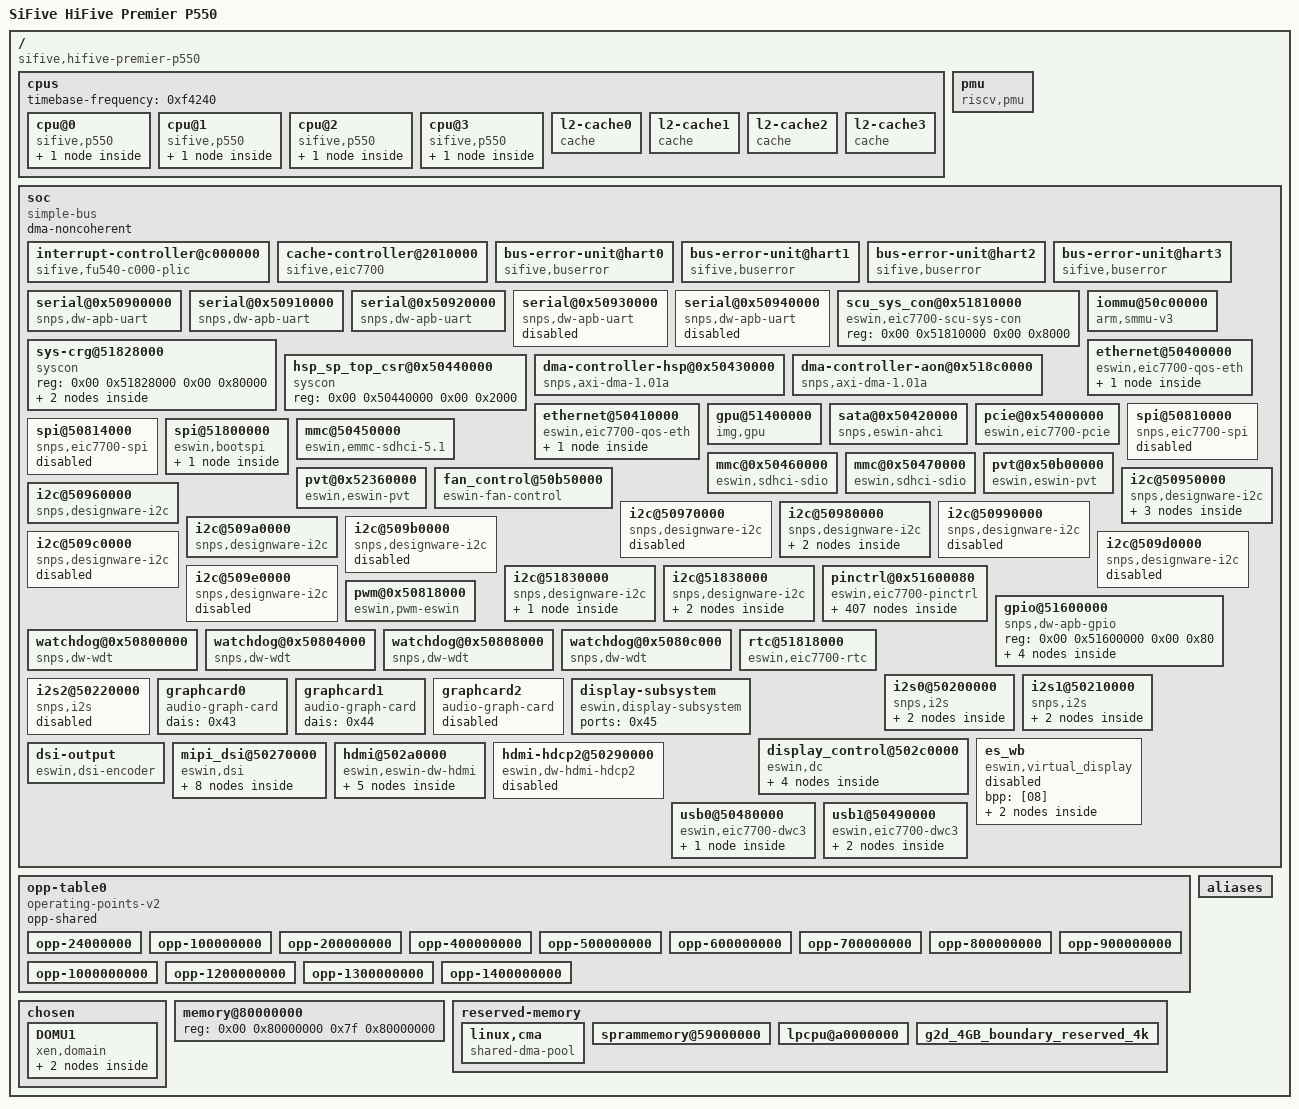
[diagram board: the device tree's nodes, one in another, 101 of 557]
/dts-v1/;

/ {
	#address-cells = <0x02>;
	#size-cells = <0x02>;
	compatible = "sifive,hifive-premier-p550", "eswin,eic7700";
	riscv,physical-memory-regions = <0x00 0x00 0x200 0x00 0x03 0x00 0x00 0x80000000 0x0f 0x80000000 0x1eb7 0x00 0xc0 0x00 0x10 0x00 0x1000e07 0x00>;
	model = "SiFive HiFive Premier P550";

	cpus {
		#address-cells = <0x01>;
		#size-cells = <0x00>;
		timebase-frequency = <0xf4240>;

		cpu@0 {
			compatible = "sifive,p550", "riscv";
			clocks = <0x01 0x1f4>;
			clock-frequency = <0x00>;
			device_type = "cpu";
			d-cache-block-size = <0x40>;
			d-cache-sets = <0x80>;
			d-cache-size = <0x8000>;
			d-tlb-sets = <0x01>;
			d-tlb-size = <0x20>;
			i-cache-block-size = <0x40>;
			i-cache-sets = <0x80>;
			i-cache-size = <0x8000>;
			i-tlb-sets = <0x01>;
			i-tlb-size = <0x20>;
			mmu-type = "riscv,sv48";
			next-level-cache = <0x02>;
			operating-points-v2 = <0x03>;
			reg = <0x00>;
			riscv,isa-base = "rv64i";
			riscv,isa-extensions = "i", "m", "a", "f", "d", "c", "h", "zicsr", "zifencei", "zba", "zbb", "sscofpmf";
			sifive,buserror = <0x04>;
			tlb-split;

			interrupt-controller {
				#interrupt-cells = <0x01>;
				compatible = "riscv,cpu-intc";
				interrupt-controller;
				phandle = <0x0c>;
			};
		};

		cpu@1 {
			compatible = "sifive,p550", "riscv";
			clocks = <0x01 0x1f5>;
			clock-frequency = <0x00>;
			device_type = "cpu";
			d-cache-block-size = <0x40>;
			d-cache-sets = <0x80>;
			d-cache-size = <0x8000>;
			d-tlb-sets = <0x01>;
			d-tlb-size = <0x20>;
			i-cache-block-size = <0x40>;
			i-cache-sets = <0x80>;
			i-cache-size = <0x8000>;
			i-tlb-sets = <0x01>;
			i-tlb-size = <0x20>;
			mmu-type = "riscv,sv48";
			next-level-cache = <0x05>;
			operating-points-v2 = <0x03>;
			reg = <0x01>;
			riscv,isa-base = "rv64i";
			riscv,isa-extensions = "i", "m", "a", "f", "d", "c", "h", "zicsr", "zifencei", "zba", "zbb", "sscofpmf";
			sifive,buserror = <0x06>;
			tlb-split;

			interrupt-controller {
				#interrupt-cells = <0x01>;
				compatible = "riscv,cpu-intc";
				interrupt-controller;
				phandle = <0x0d>;
			};
		};

		cpu@2 {
			compatible = "sifive,p550", "riscv";
			clocks = <0x01 0x1f6>;
			clock-frequency = <0x00>;
			device_type = "cpu";
			d-cache-block-size = <0x40>;
			d-cache-sets = <0x80>;
			d-cache-size = <0x8000>;
			d-tlb-sets = <0x01>;
			d-tlb-size = <0x20>;
			i-cache-block-size = <0x40>;
			i-cache-sets = <0x80>;
			i-cache-size = <0x8000>;
			i-tlb-sets = <0x01>;
			i-tlb-size = <0x20>;
			mmu-type = "riscv,sv48";
			next-level-cache = <0x07>;
			operating-points-v2 = <0x03>;
			reg = <0x02>;
			riscv,isa-base = "rv64i";
			riscv,isa-extensions = "i", "m", "a", "f", "d", "c", "h", "zicsr", "zifencei", "zba", "zbb", "sscofpmf";
			sifive,buserror = <0x08>;
			tlb-split;

			interrupt-controller {
				#interrupt-cells = <0x01>;
				compatible = "riscv,cpu-intc";
				interrupt-controller;
				phandle = <0x0e>;
			};
		};

		cpu@3 {
			compatible = "sifive,p550", "riscv";
			clocks = <0x01 0x1f7>;
			clock-frequency = <0x00>;
			device_type = "cpu";
			d-cache-block-size = <0x40>;
			d-cache-sets = <0x80>;
			d-cache-size = <0x8000>;
			d-tlb-sets = <0x01>;
			d-tlb-size = <0x20>;
			i-cache-block-size = <0x40>;
			i-cache-sets = <0x80>;
			i-cache-size = <0x8000>;
			i-tlb-sets = <0x01>;
			i-tlb-size = <0x20>;
			mmu-type = "riscv,sv48";
			next-level-cache = <0x09>;
			operating-points-v2 = <0x03>;
			reg = <0x03>;
			riscv,isa-base = "rv64i";
			riscv,isa-extensions = "i", "m", "a", "f", "d", "c", "h", "zicsr", "zifencei", "zba", "zbb", "sscofpmf";
			sifive,buserror = <0x0a>;
			tlb-split;

			interrupt-controller {
				#interrupt-cells = <0x01>;
				compatible = "riscv,cpu-intc";
				interrupt-controller;
				phandle = <0x0f>;
			};
		};

		l2-cache0 {
			compatible = "cache";
			cache-block-size = <0x40>;
			cache-level = <0x02>;
			cache-sets = <0x200>;
			cache-size = <0x40000>;
			cache-unified;
			next-level-cache = <0x0b>;
			phandle = <0x02>;
		};

		l2-cache1 {
			compatible = "cache";
			cache-block-size = <0x40>;
			cache-level = <0x02>;
			cache-sets = <0x200>;
			cache-size = <0x40000>;
			cache-unified;
			next-level-cache = <0x0b>;
			phandle = <0x05>;
		};

		l2-cache2 {
			compatible = "cache";
			cache-block-size = <0x40>;
			cache-level = <0x02>;
			cache-sets = <0x200>;
			cache-size = <0x40000>;
			cache-unified;
			next-level-cache = <0x0b>;
			phandle = <0x07>;
		};

		l2-cache3 {
			compatible = "cache";
			cache-block-size = <0x40>;
			cache-level = <0x02>;
			cache-sets = <0x200>;
			cache-size = <0x40000>;
			cache-unified;
			next-level-cache = <0x0b>;
			phandle = <0x09>;
		};
	};

	pmu {
		compatible = "riscv,pmu";
		riscv,event-to-mhpmcounters = <0x01 0x01 0x01 0x02 0x02 0x02 0x04 0x06 0x78 0x10009 0x10009 0x78 0x10019 0x10019 0x78 0x10021 0x10021 0x78>;
		riscv,event-to-mhpmevent = <0x04 0x00 0x202 0x05 0x00 0x4000 0x06 0x00 0x2001 0x10009 0x00 0x102 0x10019 0x00 0x1002 0x10021 0x00 0x802>;
		riscv,raw-event-to-mhpmcounters = <0x00 0x00 0xffffffff 0xff 0x78 0x00 0x01 0xffffffff 0xfffe07ff 0x78 0x00 0x02 0xffffffff 0xfffe00ff 0x78 0x00 0x03 0xfffffffc 0xff 0x78 0x00 0x04 0xffffffc0 0xff 0x78 0x00 0x05 0xffffffff 0xfffffdff 0x78 0x00 0x06 0xfffffe00 0x110204ff 0x78 0x00 0x07 0xffffffff 0xf00000ff 0x78 0x00 0x08 0xfffffe04 0xff 0x78 0x00 0x09 0xffffffff 0xffffc0ff 0x78 0x00 0x0a 0xffffffff 0xf00000ff 0x78 0x00 0x0b 0xffffffff 0xfffffcff 0x78 0x00 0x0c 0xfffffff0 0xff 0x78 0x00 0x0d 0xffffffff 0x800000ff 0x78 0x00 0x0e 0xffffffff 0xf80000ff 0x78 0x00 0x0f 0xfffffffc 0xff 0x78>;
	};

	soc {
		#address-cells = <0x02>;
		#size-cells = <0x02>;
		compatible = "simple-bus";
		ranges;
		dma-noncoherent;

		interrupt-controller@c000000 {
			compatible = "sifive,fu540-c000-plic", "sifive,plic-1.0.0";
			reg = <0x00 0xc000000 0x00 0x4000000>;
			#address-cells = <0x00>;
			#interrupt-cells = <0x01>;
			interrupt-controller;
			interrupts-extended = <0x0c 0xffffffff 0x0c 0x09 0x0d 0xffffffff 0x0d 0x09 0x0e 0xffffffff 0x0e 0x09 0x0f 0xffffffff 0x0f 0x09>;
			riscv,ndev = <0x208>;
			phandle = <0x10>;
		};

		cache-controller@2010000 {
			compatible = "sifive,eic7700";
			cache-block-size = <0x40>;
			cache-level = <0x03>;
			cache-sets = <0x1000>;
			cache-size = <0x400000>;
			cache-unified;
			interrupt-parent = <0x10>;
			interrupts = <0x01 0x03 0x04 0x02>;
			reg = <0x00 0x2010000 0x00 0x4000>;
			phandle = <0x0b>;
		};

		bus-error-unit@hart0 {
			compatible = "sifive,buserror";
			interrupt-parent = <0x10>;
			interrupts = <0x205>;
			reg = <0x00 0x1700000 0x00 0x1000>;
			phandle = <0x04>;
		};

		bus-error-unit@hart1 {
			compatible = "sifive,buserror";
			interrupt-parent = <0x10>;
			interrupts = <0x206>;
			reg = <0x00 0x1701000 0x00 0x1000>;
			phandle = <0x06>;
		};

		bus-error-unit@hart2 {
			compatible = "sifive,buserror";
			interrupt-parent = <0x10>;
			interrupts = <0x207>;
			reg = <0x00 0x1702000 0x00 0x1000>;
			phandle = <0x08>;
		};

		bus-error-unit@hart3 {
			compatible = "sifive,buserror";
			interrupt-parent = <0x10>;
			interrupts = <0x208>;
			reg = <0x00 0x1703000 0x00 0x1000>;
			phandle = <0x0a>;
		};

		serial@0x50900000 {
			compatible = "snps,dw-apb-uart";
			clock-frequency = <0xbebc200>;
			interrupt-parent = <0x10>;
			interrupts = <0x64>;
			reg = <0x00 0x50900000 0x00 0x10000>;
			reg-shift = <0x02>;
			reg-io-width = <0x04>;
			status = "okay";
		};

		serial@0x50910000 {
			compatible = "snps,dw-apb-uart";
			clock-frequency = <0xbebc200>;
			interrupt-parent = <0x10>;
			interrupts = <0x65>;
			reg = <0x00 0x50910000 0x00 0x10000>;
			reg-shift = <0x02>;
			reg-io-width = <0x04>;
			status = "okay";
		};

		serial@0x50920000 {
			compatible = "snps,dw-apb-uart";
			clock-frequency = <0xbebc200>;
			interrupt-parent = <0x10>;
			interrupts = <0x66>;
			reg = <0x00 0x50920000 0x00 0x10000>;
			reg-shift = <0x02>;
			reg-io-width = <0x04>;
			status = "okay";
		};

		serial@0x50930000 {
			compatible = "snps,dw-apb-uart";
			clock-frequency = <0xbebc200>;
			interrupt-parent = <0x10>;
			interrupts = <0x67>;
			reg = <0x00 0x50930000 0x00 0x10000>;
			reg-shift = <0x02>;
			reg-io-width = <0x04>;
			status = "disabled";
		};

		serial@0x50940000 {
			compatible = "snps,dw-apb-uart";
			clock-frequency = <0xbebc200>;
			interrupt-parent = <0x10>;
			interrupts = <0x68>;
			reg = <0x00 0x50940000 0x00 0x10000>;
			reg-shift = <0x02>;
			reg-io-width = <0x04>;
			status = "disabled";
		};

		scu_sys_con@0x51810000 {
			compatible = "eswin,eic7700-scu-sys-con", "syscon", "simple-mfd";
			#syscon-cells = <0x02>;
			#size-cells = <0x02>;
			reg = <0x00 0x51810000 0x00 0x8000>;
			phandle = <0x11>;
		};

		sys-crg@51828000 {
			compatible = "syscon", "simple-mfd";
			reg = <0x00 0x51828000 0x00 0x80000>;
			phandle = <0x15>;

			reset-controller {
				compatible = "eswin,eic7700-reset";
				#reset-cells = <0x02>;
				status = "okay";
				phandle = <0x12>;
			};

			clock-controller {
				compatible = "eswin,eic7700-clock";
				#clock-cells = <0x01>;
				status = "okay";
				phandle = <0x01>;
			};
		};

		hsp_sp_top_csr@0x50440000 {
			compatible = "syscon";
			#size-cells = <0x02>;
			reg = <0x00 0x50440000 0x00 0x2000>;
			phandle = <0x14>;
		};

		iommu@50c00000 {
			compatible = "arm,smmu-v3";
			eswin,syscfg = <0x11 0x3fc>;
			interrupt-parent = <0x10>;
			interrupts = <0x164 0x168 0x165 0x166>;
			interrupt-names = "eventq", "gerror", "priq", "cmdq-sync";
			#iommu-cells = <0x01>;
			reg = <0x00 0x50c00000 0x00 0x100000>;
			resets = <0x12 0x05 0x01 0x12 0x05 0x02 0x12 0x05 0x10 0x12 0x05 0x20 0x12 0x05 0x40 0x12 0x05 0x80 0x12 0x05 0x100 0x12 0x05 0x200 0x12 0x05 0x400 0x12 0x05 0x800>;
			reset-names = "axi_rst", "cfg_rst", "tbu0_rst", "tbu1_rst", "tbu2_rst", "tbu3_rst", "tbu4_rst", "tbu5_rst", "tbu6_rst", "tbu7_rst";
			status = "okay";
			phandle = <0x13>;
		};

		dma-controller-hsp@0x50430000 {
			compatible = "snps,axi-dma-1.01a";
			reg = <0x00 0x50430000 0x00 0x10000>;
			interrupt-parent = <0x10>;
			interrupts = <0x39>;
			clocks = <0x01 0x2b2>;
			clock-names = "core-clk";
			#dma-cells = <0x02>;
			dma-channels = <0x0c>;
			snps,dma-masters = <0x01>;
			snps,priority = <0x00 0x01 0x02 0x03 0x04 0x05 0x06 0x07 0x08 0x09 0x0a 0x0b>;
			snps,data-width = <0x02>;
			snps,block-size = <0x80000 0x80000 0x80000 0x80000 0x80000 0x80000 0x80000 0x80000 0x80000 0x80000 0x80000 0x80000>;
			snps,axi-max-burst-len = <0x10>;
			snps,max-msize = <0x40>;
			resets = <0x12 0x07 0x4000 0x12 0x07 0x100000>;
			reset-names = "arst", "prst";
			iommus = <0x13 0x01>;
			tbus = <0x02>;
			eswin,hsp_sp_csr = <0x14 0x104c>;
			eswin,syscfg = <0x11 0x3004 0x370>;
			status = "okay";
		};

		dma-controller-aon@0x518c0000 {
			compatible = "snps,axi-dma-1.01a";
			#size-cells = <0x02>;
			#address-cells = <0x02>;
			reg = <0x00 0x518c0000 0x00 0x10000>;
			interrupt-parent = <0x10>;
			interrupts = <0x121>;
			clocks = <0x01 0x266>;
			clock-names = "core-clk";
			#dma-cells = <0x02>;
			dma-channels = <0x10>;
			dma-ranges = <0x00 0x80000000 0x00 0x80000000 0x100 0x00>;
			snps,dma-masters = <0x02>;
			snps,priority = <0x00 0x01 0x02 0x03 0x04 0x05 0x06 0x07 0x08 0x09 0x0a 0x0b 0x0c 0x0d 0x0e 0x0f>;
			snps,data-width = <0x03>;
			snps,block-size = <0x80000 0x80000 0x80000 0x80000 0x80000 0x80000 0x80000 0x80000 0x80000 0x80000 0x80000 0x80000 0x80000 0x80000 0x80000 0x80000>;
			snps,axi-max-burst-len = <0x20>;
			snps,max-msize = <0x40>;
			resets = <0x12 0x27 0x01 0x12 0x27 0x02>;
			reset-names = "arst", "prst";
			iommus = <0x13 0x1a>;
			tbus = <0x04>;
			eswin,syscfg = <0x11 0x3004 0x370>;
			status = "okay";
			phandle = <0x1d>;
		};

		ethernet@50400000 {
			compatible = "eswin,eic7700-qos-eth";
			clocks = <0x01 0x226 0x01 0x227 0x01 0x228>;
			clock-names = "app", "stmmaceth", "tx";
			eswin,hsp_sp_csr = <0x14 0x1030 0x100 0x108>;
			eswin,syscrg_csr = <0x15 0x148 0x14c>;
			id = <0x00>;
			interrupts = <0x3d>;
			interrupt-names = "macirq";
			interrupt-parent = <0x10>;
			phy-mode = "rgmii";
			reg = <0x00 0x50400000 0x00 0x10000>;
			resets = <0x12 0x07 0x4000000>;
			reset-names = "ethrst";
			snps,axi-config = <0x16>;
			tbus = <0x02>;
			status = "okay";
			pinctrl-names = "default";
			pinctrl-0 = <0x17>;
			rst-gpios = <0x18 0x0a 0x01>;
			eswin,rgmiisel = <0x19 0x290 0x03>;
			eswin,led-cfgs = <0x6100 0xa40 0x420>;

			stmmac-axi-config {
				snps,blen = <0x00 0x00 0x00 0x00 0x10 0x08 0x04>;
				snps,rd_osr_lmt = <0x02>;
				snps,wr_osr_lmt = <0x02>;
				snps,lpi_en = <0x00>;
				phandle = <0x16>;
			};
		};

		ethernet@50410000 {
			compatible = "eswin,eic7700-qos-eth";
			clocks = <0x01 0x226 0x01 0x227 0x01 0x229>;
			clock-names = "app", "stmmaceth", "tx";
			eswin,hsp_sp_csr = <0x14 0x1034 0x200 0x208>;
			eswin,syscrg_csr = <0x15 0x148 0x14c>;
			id = <0x01>;
			interrupts = <0x46>;
			interrupt-names = "macirq";
			interrupt-parent = <0x10>;
			phy-mode = "rgmii";
			reg = <0x00 0x50410000 0x00 0x10000>;
			resets = <0x12 0x07 0x2000000>;
			reset-names = "ethrst";
			tbus = <0x02>;
			snps,axi-config = <0x1a>;
			status = "okay";
			pinctrl-names = "default";
			pinctrl-0 = <0x1b>;
			rst-gpios = <0x18 0x0f 0x01>;
			eswin,rgmiisel = <0x19 0x294 0x03>;
			eswin,led-cfgs = <0x6100 0xa40 0x420>;

			stmmac-axi-config {
				snps,blen = <0x00 0x00 0x00 0x00 0x10 0x08 0x04>;
				snps,rd_osr_lmt = <0x02>;
				snps,wr_osr_lmt = <0x02>;
				snps,lpi_en = <0x00>;
				phandle = <0x1a>;
			};
		};

		gpu@51400000 {
			compatible = "img,gpu";
			#address-cells = <0x02>;
			#size-cells = <0x02>;
			reg = <0x00 0x51400000 0x00 0xfffff>;
			clocks = <0x01 0x20b 0x01 0x20c 0x01 0x20d>;
			clock-names = "aclk", "gray_clk", "cfg_clk";
			resets = <0x12 0x01 0x01 0x12 0x01 0x02 0x12 0x01 0x04 0x12 0x01 0x08 0x12 0x01 0x10>;
			reset-names = "axi", "cfg", "gray", "jones", "spu";
			interrupt-parent = <0x10>;
			interrupts = <0x0f>;
			status = "okay";
		};

		sata@0x50420000 {
			compatible = "snps,eswin-ahci";
			eswin,hsp_sp_csr = <0x14 0x1050>;
			interrupt-parent = <0x10>;
			interrupt-names = "intrq", "msi", "pme";
			interrupts = <0x3a 0x3b 0x3c>;
			iommus = <0x13 0x0e>;
			ports-implemented = <0x01>;
			reg = <0x00 0x50420000 0x00 0x10000>;
			resets = <0x12 0x07 0x200 0x12 0x07 0x400 0x12 0x07 0x800 0x12 0x07 0x1000 0x12 0x07 0x8000000>;
			reset-names = "asic0", "oob", "pmalive", "rbc", "apb";
			#size-cells = <0x02>;
			tbus = <0x02>;
			dma-ranges = <0x00 0x00 0x00 0xc0000000 0x200 0x00>;
			status = "okay";
			pinctrl-names = "default";
			pinctrl-0 = <0x1c>;
		};

		pcie@0x54000000 {
			compatible = "eswin,eic7700-pcie";
			#address-cells = <0x03>;
			#size-cells = <0x02>;
			clocks = <0x01 0x232 0x01 0x233 0x01 0x234 0x01 0x235>;
			clock-names = "pcie_aclk", "pcie_cfg_clk", "pcie_cr_clk", "pcie_aux_clk";
			device_type = "pci";
			#interrupt-cells = <0x01>;
			interrupts = <0xdc 0xb3 0xb4 0xb5 0xb6 0xb7 0xb8 0xb9 0xba>;
			interrupt-names = "msi", "inta", "intb", "intc", "intd";
			interrupt-parent = <0x10>;
			interrupt-map-mask = <0x00 0x00 0x00 0x07>;
			interrupt-map = <0x00 0x00 0x00 0x01 0x10 0xb3 0x00 0x00 0x00 0x02 0x10 0xb4 0x00 0x00 0x00 0x03 0x10 0xb5 0x00 0x00 0x00 0x04 0x10 0xb6>;
			iommus = <0x13 0xfe0000>;
			iommu-map = <0x00 0x13 0xff0000 0xffffff>;
			num-lanes = <0x04>;
			resets = <0x12 0x08 0x01 0x12 0x08 0x02 0x12 0x08 0x04>;
			reset-names = "pcie_cfg", "pcie_powerup", "pcie_pwren";
			reg = <0x00 0x54000000 0x00 0x4000000 0x00 0x40000000 0x00 0x800000 0x00 0x50000000 0x00 0x100000>;
			reg-names = "dbi", "config", "mgmt";
			bus-range = <0x00 0xff>;
			ranges = <0x81000000 0x00 0x40800000 0x00 0x40800000 0x00 0x800000 0x82000000 0x00 0x41000000 0x00 0x41000000 0x00 0xf000000 0xc3000000 0x80 0x00 0x80 0x00 0x02 0x00>;
			gen-x = <0x03>;
			lane-x = <0x04>;
			tbus = <0x03>;
			status = "okay";
		};

		spi@50810000 {
			compatible = "snps,eic7700-spi";
			#address-cells = <0x01>;
			#size-cells = <0x00>;
			reg = <0x00 0x50810000 0x00 0x4000>;
			spi-max-frequency = "", "I>";
			clocks = <0x01 0x29c>;
			clock-names = "clk";
			interrupt-parent = <0x10>;
			interrupts = <0x5b>;
			resets = <0x12 0x10 0x01>;
			reset-names = "spi";
			eswin,spi_dma = <0x1d>;
			dmas = <0x1d 0x26 0x03 0x1d 0x27 0x03>;
			dma-names = "rx", "tx";
			status = "disabled";
		};

		spi@50814000 {
			compatible = "snps,eic7700-spi";
			#address-cells = <0x01>;
			#size-cells = <0x00>;
			reg = <0x00 0x50814000 0x00 0x4000>;
			spi-max-frequency = "", "I>";
			clocks = <0x01 0x29d>;
			clock-names = "clk";
			interrupt-parent = <0x10>;
			interrupts = <0x5c>;
			resets = <0x12 0x10 0x02>;
			reset-names = "spi";
			eswin,spi_dma = <0x1d>;
			dmas = <0x1d 0x24 0x04 0x1d 0x25 0x04>;
			dma-names = "rx", "tx";
			status = "disabled";
		};

		spi@51800000 {
			compatible = "eswin,bootspi";
			#address-cells = <0x01>;
			#size-cells = <0x00>;
			clocks = <0x01 0x205 0x01 0x204>;
			clock-names = "cfg_clk", "clk";
			reg = <0x00 0x51800000 0x00 0x8000 0x00 0x51828000 0x00 0x8000 0x00 0x5c000000 0x00 0x8000>;
			resets = <0x12 0x24 0x02>;
			reset-names = "rst";
			reg-io-width = <0x04>;
			spi-max-frequency = "", "I>";
			status = "okay";
			num-cs = <0x01>;
			cs-gpios = <0x18 0x00 0x01>;

			spi-flash@0 {
				compatible = "winbond,w25q128jw", "jedec,spi-nor";
				reg = <0x00>;
				#address-cells = <0x01>;
				#size-cells = <0x01>;
				spi-max-frequency = "", "I>";
				rx-sample-delay-ns = <0x0a>;
			};
		};

		mmc@50450000 {
			compatible = "eswin,emmc-sdhci-5.1";
			#clock-cells = <0x00>;
			clocks = <0x01 0x22a 0x01 0x222>;
			clock-names = "clk_xin", "clk_ahb";
			clock-output-names = "emmc_cardclock";
			assigned-clocks = <0x01 0x22a>;
			assigned-clock-rates = <0xbebc200>;
			reg = <0x00 0x50450000 0x00 0x10000>;
			interrupt-parent = <0x10>;
			interrupts = <0x4f>;
			resets = <0x12 0x07 0x40 0x12 0x07 0x08 0x12 0x07 0x80000 0x12 0x07 0x800000>;
			reset-names = "txrx_rst", "phy_rst", "prstn", "arstn";
			disable-cqe-dcmd;
			bus-width = <0x08>;
			non-removable;
			mmc-hs400-1_8v;
			max-frequency = <0xbebc200>;
			#size-cells = <0x02>;
			iommus = <0x13 0x0f>;
			tbus = <0x02>;
			dma-ranges = <0x00 0x00 0x00 0xc0000000 0x01 0x00>;
			eswin,hsp_sp_csr = <0x14 0x1038>;
			status = "okay";
			delay_code = <0x17>;
			drive-impedance-ohm = <0x32>;
			enable-cmd-pullup;
			enable-data-pullup;
			pinctrl-names = "default";
			pinctrl-0 = <0x1e>;
		};

		mmc@0x50460000 {
			compatible = "eswin,sdhci-sdio";
			reg = <0x00 0x50460000 0x00 0x10000>;
			interrupt-parent = <0x10>;
			interrupts = <0x51>;
			clocks = <0x01 0x22b 0x01 0x222 0x01 0x0c 0x01 0x23>;
			clock-names = "clk_xin", "clk_ahb", "clk_spll2_fout3", "clk_mux1_1";
			clock-output-names = "sdio0_cardclock";
			#clock-cells = <0x00>;
			resets = <0x12 0x07 0x80 0x12 0x07 0x10 0x12 0x07 0x40000 0x12 0x07 0x400000>;
			reset-names = "txrx_rst", "phy_rst", "prstn", "arstn";
			core-clk-reg = <0x51828164>;
			clock-frequency = <0xc65d400>;
			max-frequency = <0xc65d400>;
			#size-cells = <0x02>;
			dma-ranges = <0x00 0x20000000 0x00 0xc0000000 0x00 0x40000000>;
			iommus = <0x13 0x10>;
			tbus = <0x02>;
			eswin,hsp_sp_csr = <0x14 0x103c>;
			bus-width = <0x04>;
			sdio-id = <0x00>;
			status = "okay";
			delay_code = <0x29>;
			drive-impedance-ohm = <0x21>;
			enable-cmd-pullup;
			enable-data-pullup;
			no-sdio;
			no-mmc;
		};

		mmc@0x50470000 {
			compatible = "eswin,sdhci-sdio";
			reg = <0x00 0x50470000 0x00 0x10000>;
			interrupt-parent = <0x10>;
			interrupts = <0x53>;
			clocks = <0x01 0x22c 0x01 0x222 0x01 0x0c 0x01 0x23>;
			clock-names = "clk_xin", "clk_ahb", "clk_spll2_fout3", "clk_mux1_1";
			clock-output-names = "sdio1_cardclock";
			#clock-cells = <0x00>;
			resets = <0x12 0x07 0x100 0x12 0x07 0x20 0x12 0x07 0x20000 0x12 0x07 0x200000>;
			reset-names = "txrx_rst", "phy_rst", "prstn", "arstn";
			core-clk-reg = <0x51828168>;
			clock-frequency = <0xc65d400>;
			max-frequency = <0xc65d400>;
			#size-cells = <0x02>;
			dma-ranges = <0x00 0x20000000 0x00 0xc0000000 0x00 0x40000000>;
			iommus = <0x13 0x11>;
			tbus = <0x02>;
			eswin,hsp_sp_csr = <0x14 0x1040>;
			bus-width = <0x04>;
			sdio-id = <0x01>;
			status = "okay";
			delay_code = <0x29>;
			drive-impedance-ohm = <0x21>;
			enable-cmd-pullup;
			enable-data-pullup;
			non-removable;
			no-sd;
			no-mmc;
		};

		pvt@0x50b00000 {
			compatible = "eswin,eswin-pvt";
			#address-cells = <0x01>;
			#size-cells = <0x00>;
			clocks = <0x01 0x25f>;
			clock-names = "pvt_clk";
			interrupts = <0x15d>;
			interrupt-parent = <0x10>;
			resets = <0x12 0x0b 0x01>;
			reset-names = "pvt_rst";
			reg = <0x00 0x50b00000 0x00 0x10000>;
			status = "okay";
		};

		pvt@0x52360000 {
			compatible = "eswin,eswin-pvt";
			#address-cells = <0x01>;
			#size-cells = <0x00>;
			clocks = <0x01 0x260>;
			clock-names = "pvt_clk";
			interrupts = <0x15e>;
			interrupt-parent = <0x10>;
			resets = <0x12 0x0b 0x02>;
			reset-names = "pvt_rst";
			reg = <0x00 0x52360000 0x00 0x20000>;
			status = "okay";
		};

		fan_control@50b50000 {
			compatible = "eswin-fan-control";
			reg = <0x00 0x50b50000 0x00 0x10000>;
			clocks = <0x01 0x2a7>;
			clock-names = "pclk";
			interrupt-parent = <0x10>;
			interrupt-names = "fanirq";
			interrupts = <0x162>;
			pulses-per-revolution = <0x02>;
			pwm-minimum-period = <0x3e8>;
			pwms = <0x1f 0x00 0x186a0>;
			pinctrl-names = "default";
			pinctrl-0 = <0x20>;
			resets = <0x12 0x0a 0x01>;
			reset-names = "fan_rst";
			status = "okay";
		};

		i2c@50950000 {
			compatible = "snps,designware-i2c";
			reg = <0x00 0x50950000 0x00 0x8000>;
			clocks = <0x01 0x28e>;
			clock-names = "pclk";
			clock-frequency = <0x186a0>;
			resets = <0x12 0x09 0x01>;
			reset-names = "rst";
			interrupts = <0x69>;
			interrupt-parent = <0x10>;
			#address-cells = <0x01>;
			#size-cells = <0x00>;
			status = "okay";

			es8388-0@11 {
				compatible = "eswin,es8388";
				reg = <0x11>;
				#sound-dai-cells = <0x00>;
				eswin-plat = <0x02>;
				pinctrl-names = "default";
				pinctrl-0 = <0x21 0x22>;
				front-jack-gpios = <0x23 0x00 0x00>;
				back-jack-gpios = <0x23 0x1c 0x00>;

				port {

					endpoint {
						system-clock-frequency = <0xbb8000>;
						remote-endpoint = <0x24>;
						phandle = <0x42>;
					};
				};
			};
		};

		i2c@50960000 {
			compatible = "snps,designware-i2c";
			reg = <0x00 0x50960000 0x00 0x10000>;
			clock-frequency = <0x186a0>;
			clocks = <0x01 0x28f>;
			clock-names = "pclk";
			resets = <0x12 0x09 0x02>;
			reset-names = "rst";
			interrupts = <0x6a>;
			interrupt-parent = <0x10>;
			#address-cells = <0x01>;
			#size-cells = <0x00>;
			status = "okay";
		};

		i2c@50970000 {
			compatible = "snps,designware-i2c";
			reg = <0x00 0x50970000 0x00 0x8000>;
			clock-frequency = <0x186a0>;
			clocks = <0x01 0x290>;
			clock-names = "pclk";
			resets = <0x12 0x09 0x04>;
			reset-names = "rst";
			interrupts = <0x6b>;
			interrupt-parent = <0x10>;
			#address-cells = <0x01>;
			#size-cells = <0x00>;
			status = "disabled";
		};

		i2c@50980000 {
			compatible = "snps,designware-i2c";
			reg = <0x00 0x50980000 0x00 0x8000>;
			clock-frequency = <0x186a0>;
			clocks = <0x01 0x291>;
			clock-names = "pclk";
			resets = <0x12 0x09 0x08>;
			reset-names = "rst";
			interrupts = <0x6c>;
			interrupt-parent = <0x10>;
			#address-cells = <0x01>;
			#size-cells = <0x00>;
			status = "okay";

			fusb303b@21 {
				compatible = "fcs,fusb303b";
				status = "okay";
				reg = <0x21>;
				eswin,syscfg = <0x11 0x3c0 0x0c>;
				pinctrl-names = "default";
				pinctrl-0 = <0x25>;
				int-gpios = <0x23 0x05 0x00>;

				connector {
					compatible = "usb-c-connector";
					label = "USB-C";
					data-role = "host";
				};
			};
		};

		i2c@50990000 {
			compatible = "snps,designware-i2c";
			reg = <0x00 0x50990000 0x00 0x8000>;
			clock-frequency = <0x186a0>;
			clocks = <0x01 0x292>;
			clock-names = "pclk";
			resets = <0x12 0x09 0x10>;
			reset-names = "rst";
			interrupts = <0x6d>;
			interrupt-parent = <0x10>;
			#address-cells = <0x01>;
			#size-cells = <0x00>;
			status = "disabled";
		};

		i2c@509a0000 {
			compatible = "snps,designware-i2c";
			reg = <0x00 0x509a0000 0x00 0x8000>;
			clock-frequency = <0x186a0>;
			clocks = <0x01 0x293>;
			clock-names = "pclk";
			resets = <0x12 0x09 0x20>;
			reset-names = "rst";
			interrupts = <0x6e>;
			interrupt-parent = <0x10>;
			#address-cells = <0x01>;
			#size-cells = <0x00>;
			status = "okay";
		};

		i2c@509b0000 {
			compatible = "snps,designware-i2c";
			reg = <0x00 0x509b0000 0x00 0x8000>;
			clock-frequency = <0x186a0>;
			clocks = <0x01 0x294>;
			clock-names = "pclk";
			resets = <0x12 0x09 0x40>;
			reset-names = "rst";
			interrupts = <0x6f>;
			interrupt-parent = <0x10>;
			#address-cells = <0x01>;
			#size-cells = <0x00>;
			status = "disabled";
		};

		i2c@509c0000 {
			compatible = "snps,designware-i2c";
			reg = <0x00 0x509c0000 0x00 0x8000>;
			clock-frequency = <0x186a0>;
			clocks = <0x01 0x295>;
			clock-names = "pclk";
			resets = <0x12 0x09 0x80>;
			reset-names = "rst";
			interrupts = <0x70>;
			interrupt-parent = <0x10>;
			#address-cells = <0x01>;
			#size-cells = <0x00>;
			status = "disabled";
		};

		i2c@509d0000 {
			compatible = "snps,designware-i2c";
			reg = <0x00 0x509d0000 0x00 0x8000>;
			clock-frequency = <0x186a0>;
			clocks = <0x01 0x296>;
			clock-names = "pclk";
			resets = <0x12 0x09 0x100>;
			reset-names = "rst";
			interrupts = <0x71>;
			interrupt-parent = <0x10>;
			#address-cells = <0x01>;
			#size-cells = <0x00>;
			status = "disabled";
		};

		i2c@509e0000 {
			compatible = "snps,designware-i2c";
			reg = <0x00 0x509e0000 0x00 0x8000>;
			clock-frequency = <0x186a0>;
			clocks = <0x01 0x297>;
			clock-names = "pclk";
			resets = <0x12 0x09 0x200>;
			reset-names = "rst";
			interrupts = <0x72>;
			interrupt-parent = <0x10>;
			#address-cells = <0x01>;
			#size-cells = <0x00>;
			status = "disabled";
		};

		i2c@51830000 {
			compatible = "snps,designware-i2c";
			reg = <0x00 0x51830000 0x00 0x8000>;
			clock-frequency = <0x186a0>;
			clocks = <0x01 0x29f>;
			clock-names = "pclk";
			resets = <0x12 0x26 0x01>;
			reset-names = "rst";
			interrupts = <0x122>;
			interrupt-parent = <0x10>;
			eswin,i2c_dma = <0x1d>;
			dma-names = "rx", "tx";
			dmas = <0x1d 0x29 0xff 0x1d 0x2a 0xff>;
			#address-cells = <0x01>;
			#size-cells = <0x00>;
			status = "okay";
			eswin,syscfg = <0x11 0x3c0 0x10>;

			aon_eeprom@50 {
				compatible = "atmel,24c02";
				reg = <0x50>;
			};
		};

		i2c@51838000 {
			compatible = "snps,designware-i2c";
			reg = <0x00 0x51838000 0x00 0x8000>;
			clock-frequency = <0x186a0>;
			clocks = <0x01 0x2a0>;
			clock-names = "pclk";
			resets = <0x12 0x25 0x01>;
			reset-names = "rst";
			interrupts = <0x123>;
			interrupt-parent = <0x10>;
			#address-cells = <0x01>;
			#size-cells = <0x00>;
			status = "okay";
			eswin,syscfg = <0x11 0x3c0 0x0f>;
			i2c-sda-hold-time-ns = <0x40>;

			pac1934@10 {
				compatible = "microchip,pac1934";
				update_time_ms = <0x3e8>;
				eswin,chan_label = "som vdd", "soc vdd", "cpu vdd", "ddr lpvdd";
				label = "som_info";
				energy_acc_count = <0x00>;
				shunt_resistors = <0x01 0x01 0x01 0x01>;
				reg = <0x10>;
			};

			ina226@44 {
				compatible = "ti,ina226";
				#io-channel-cells = <0x01>;
				label = "sys_power";
				reg = <0x44>;
				shunt-resistor = <0x3e8>;
			};
		};

		pinctrl@0x51600080 {
			compatible = "eswin,eic7700-pinctrl", "syscon";
			reg = <0x00 0x51600080 0x00 0x1fff80>;
			status = "okay";
			pinctrl-names = "default";
			pinctrl-0 = <0x26 0x27 0x28 0x29 0x2a 0x2b 0x2c 0x2d 0x2e 0x2f 0x30 0x31 0x32 0x33 0x34 0x35 0x36 0x37 0x38 0x39 0x3a 0x3b 0x3c 0x3d 0x3e 0x3f>;
			phandle = <0x19>;

			sdio0-default {

				mux {
					groups = "sdio0_group";
					function = "sdio0_func";
				};
			};

			sdio1-default {

				mux {
					groups = "sdio1_group";
					function = "sdio1_func";
				};
			};

			por_sel-default {

				mux {
					groups = "por_sel_group";
					function = "por_sel_func";
				};
			};

			jtag0-default {

				mux {
					groups = "jtag0_group";
					function = "jtag0_func";
				};
			};

			jtag1-default {

				mux {
					groups = "jtag1_group";
					function = "jtag1_func";
				};
			};

			jtag2-default {

				mux {
					groups = "jtag2_group";
					function = "jtag2_func";
				};
			};

			pcie-default {

				mux {
					groups = "pcie_group";
					function = "pcie_func";
				};
			};

			hdmi-default {

				mux {
					groups = "hdmi_group";
					function = "hdmi_func";
				};
			};

			rgmii0-default {

				mux {
					groups = "rgmii0_group";
					function = "rgmii0_func";
				};
			};

			rgmii1-default {

				mux {
					groups = "rgmii1_group";
					function = "rgmii1_func";
				};
			};

			spi0-default {

				mux {
					groups = "spi0_group";
					function = "spi0_func";
				};
			};

			spi1-default {

				mux {
					groups = "spi1_group";
					function = "spi1_func";
				};
			};

			spi3-default {

				mux {
					groups = "spi3_group";
					function = "spi3_func";
				};
			};

			por_time_sel0-default {

				mux {
					groups = "por_time_sel0_group";
					function = "por_time_sel0_func";
				};
			};

			por_time_sel1-default {

				mux {
					groups = "por_time_sel1_group";
					function = "por_time_sel1_func";
				};
			};

			i2s0-default {

				mux {
					groups = "i2s0_group";
					function = "i2s0_func";
				};
			};

			i2s1-default {

				mux {
					groups = "i2s1_group";
					function = "i2s1_func";
				};
			};

			i2s2-default {

				mux {
					groups = "i2s2_group";
					function = "i2s2_func";
				};
			};

			usb0_pwren-default {

				mux {
					groups = "usb0_pwren_group";
					function = "usb0_pwren_func";
				};
			};

			usb1_pwren-default {

				mux {
					groups = "usb1_pwren_group";
					function = "usb1_pwren_func";
				};
			};

			i2c0-default {

				mux {
					groups = "i2c0_group";
					function = "i2c0_func";
				};
			};

			i2c1-default {

				mux {
					groups = "i2c1_group";
					function = "i2c1_func";
				};
			};

			i2c2-default {

				mux {
					groups = "i2c2_group";
					function = "i2c2_func";
				};
			};

			i2c3-default {

				mux {
					groups = "i2c3_group";
					function = "i2c3_func";
				};
			};

			i2c4-default {

				mux {
					groups = "i2c4_group";
					function = "i2c4_func";
				};
			};

			i2c5-default {

				mux {
					groups = "i2c5_group";
					function = "i2c5_func";
				};
			};

			i2c8-default {

				mux {
					groups = "i2c8_group";
					function = "i2c8_func";
				};
			};

			i2c10-default {

				mux {
					groups = "i2c10_group";
					function = "i2c10_func";
				};
			};

			i2c11-default {

				mux {
					groups = "i2c11_group";
					function = "i2c11_func";
				};
			};

			uart0-default {

				mux {
					groups = "uart0_group";
					function = "uart0_func";
				};
			};

			uart1-default {

				mux {
					groups = "uart1_group";
					function = "uart1_func";
				};
			};

			uart2-default {

				mux {
					groups = "uart2_group";
					function = "uart2_func";
				};
			};

			pwm0-default {
				phandle = <0x40>;

				mux {
					groups = "pwm0_group";
					function = "pwm0_func";
				};
			};

			fan_tach-default {
				phandle = <0x20>;

				mux {
					groups = "fan_tach_group";
					function = "fan_tach_func";
				};
			};

			mipi_csi0-default {

				mux {
					groups = "mipi_csi0_group";
					function = "mipi_csi0_func";
				};
			};

			mipi_csi1-default {

				mux {
					groups = "mipi_csi1_group";
					function = "mipi_csi1_func";
				};
			};

			mipi_csi2-default {

				mux {
					groups = "mipi_csi2_group";
					function = "mipi_csi2_func";
				};
			};

			mipi_csi3-default {

				mux {
					groups = "mipi_csi3_group";
					function = "mipi_csi3_func";
				};
			};

			mipi_csi4-default {

				mux {
					groups = "mipi_csi4_group";
					function = "mipi_csi4_func";
				};
			};

			mipi_csi5-default {

				mux {
					groups = "mipi_csi5_group";
					function = "mipi_csi5_func";
				};
			};

			s_mode-default {

				mux {
					groups = "s_mode_group";
					function = "s_mode_func";
				};
			};

			pinmux_ddr_refclk_sel-default {

				mux {
					groups = "pinmux_ddr_refclk_sel_group";
					function = "pinmux_ddr_refclk_sel_func";
				};
			};

			boot_sel-default {

				mux {
					groups = "boot_sel_group";
					function = "boot_sel_func";
				};
			};

			lpddr_ref_clk-default {

				mux {
					groups = "lpddr_ref_clk_group";
					function = "lpddr_ref_clk_func";
				};
			};

			spi2-default {

				mux1 {
					groups = "spi2_clk_group";
					function = "spi2_clk_func";
				};

				conf1 {
					groups = "spi2_clk_group";
					input-enable = <0x01>;
					bias-pull-up = <0x01>;
					bias-pull-down = <0x00>;
				};

				mux2 {
					groups = "spi2_d0_group";
					function = "spi2_d0_func";
				};

				conf2 {
					groups = "spi2_d0_group";
					input-enable = <0x01>;
					bias-pull-up = <0x01>;
					bias-pull-down = <0x00>;
				};

				mux3 {
					groups = "spi2_d1_d2_d3_group";
					function = "spi2_d1_d2_d3_func";
				};

				conf3 {
					groups = "spi2_d1_d2_d3_group";
					input-enable = <0x01>;
					bias-pull-up = <0x01>;
					bias-pull-down = <0x00>;
				};

				mux4 {
					groups = "spi2_cs_group";
					function = "spi2_cs_func";
				};
			};

			sata_act_led-default {
				phandle = <0x1c>;

				mux {
					groups = "sata_act_led_group";
					function = "sata_act_led_func";
				};

				conf {
					groups = "sata_act_led_group";
					input-enable = <0x00>;
					bias-pull-down = <0x01>;
				};
			};

			emmc_led_control-default {
				phandle = <0x1e>;

				mux {
					groups = "emmc_led_control_group";
					function = "emmc_led_control_func";
				};

				conf {
					groups = "emmc_led_control_group";
					input-enable = <0x00>;
					bias-pull-down = <0x01>;
				};
			};

			sd0_led_control-default {

				mux {
					groups = "sd0_led_control_group";
					function = "sd0_led_control_func";
				};
			};

			sd1_led_control-default {

				mux {
					groups = "sd1_led_control_group";
					function = "sd1_led_control_func";
				};
			};

			i2c6-default {

				mux {
					groups = "i2c6_group";
					function = "i2c6_func";
				};
			};

			i2c7-default {

				mux {
					groups = "i2c7_group";
					function = "i2c7_func";
				};
			};

			i2c9-default {

				mux {
					groups = "i2c9_group";
					function = "i2c9_func";
				};
			};

			pwm1-default {

				mux {
					groups = "pwm1_group";
					function = "pwm1_func";
				};
			};

			pwm2-default {

				mux {
					groups = "pwm2_group";
					function = "pwm2_func";
				};
			};

			mipi_csi_xtrig-default {

				mux {
					groups = "mipi_csi_xtrig_group";
					function = "mipi_csi_xtrig_func";
				};
			};

			uart3-default {

				mux {
					groups = "uart3_group";
					function = "uart3_func";
				};
			};

			uart4-default {

				mux {
					groups = "uart4_group";
					function = "uart4_func";
				};
			};

			gpio0-default {
				phandle = <0x21>;

				mux {
					groups = "gpio0_group";
					function = "gpio0_func";
				};

				conf {
					groups = "gpio0_group";
					input-enable = <0x01>;
					bias-pull-up = <0x01>;
				};
			};

			gpio1-default {

				mux {
					groups = "gpio1_group";
					function = "gpio1_func";
				};
			};

			gpio2-default {

				mux {
					groups = "gpio2_group";
					function = "gpio2_func";
				};
			};

			gpio3-default {

				mux {
					groups = "gpio3_group";
					function = "gpio3_func";
				};
			};

			gpio4-default {

				mux {
					groups = "gpio4_group";
					function = "gpio4_func";
				};
			};

			gpio5-default {
				phandle = <0x25>;

				mux {
					groups = "gpio5_group";
					function = "gpio5_func";
				};

				conf {
					groups = "gpio5_group";
					input-enable = <0x01>;
					bias-pull-up = <0x01>;
				};
			};

			gpio6-default {
				phandle = <0x26>;

				mux {
					groups = "gpio6_group";
					function = "gpio6_func";
				};

				conf {
					groups = "gpio6_group";
					input-enable = <0x01>;
					bias-pull-down = <0x01>;
				};
			};

			gpio7-default {
				phandle = <0x27>;

				mux {
					groups = "gpio7_group";
					function = "gpio7_func";
				};

				conf {
					groups = "gpio7_group";
					input-enable = <0x01>;
					bias-pull-down = <0x01>;
				};
			};

			gpio8-default {
				phandle = <0x28>;

				mux {
					groups = "gpio8_group";
					function = "gpio8_func";
				};

				conf {
					groups = "gpio8_group";
					input-enable = <0x01>;
					bias-pull-up = <0x01>;
				};
			};

			gpio9-default {
				phandle = <0x29>;

				mux {
					groups = "gpio9_group";
					function = "gpio9_func";
				};

				conf {
					groups = "gpio9_group";
					input-enable = <0x01>;
					bias-pull-up = <0x01>;
				};
			};

			gpio10-default {
				phandle = <0x2a>;

				mux {
					groups = "gpio10_group";
					function = "gpio10_func";
				};

				conf {
					groups = "gpio10_group";
					input-enable = <0x01>;
					bias-pull-up = <0x01>;
				};
			};

			gpio11-default {

				mux {
					groups = "gpio11_group";
					function = "gpio11_func";
				};

				conf {
					groups = "gpio11_group";
					input-enable = <0x01>;
					bias-pull-up = <0x01>;
				};
			};

			gpio12-default {

				mux {
					groups = "gpio12_group";
					function = "gpio12_func";
				};
			};

			gpio13-default {

				mux {
					groups = "gpio13_group";
					function = "gpio13_func";
				};
			};

			gpio14-default {

				mux {
					groups = "gpio14_group";
					function = "gpio14_func";
				};
			};

			gpio15-default {

				mux {
					groups = "gpio15_group";
					function = "gpio15_func";
				};
			};

			gpio16-default {

				mux {
					groups = "gpio16_group";
					function = "gpio16_func";
				};

				conf {
					groups = "gpio16_group";
					input-enable = <0x00>;
					bias-pull-down = <0x01>;
				};
			};

			gpio17-default {
				phandle = <0x2b>;

				mux {
					groups = "gpio17_group";
					function = "gpio17_func";
				};

				conf {
					groups = "gpio17_group";
					input-enable = <0x01>;
					bias-pull-down = <0x01>;
				};
			};

			gpio18-default {

				mux {
					groups = "gpio18_group";
					function = "gpio18_func";
				};

				conf {
					groups = "gpio18_group";
					input-enable = <0x01>;
					bias-pull-down = <0x01>;
				};
			};

			gpio19-default {

				mux {
					groups = "gpio19_group";
					function = "gpio19_func";
				};

				conf {
					groups = "gpio19_group";
					input-enable = <0x01>;
					bias-pull-down = <0x01>;
				};
			};

			gpio20-default {

				mux {
					groups = "gpio20_group";
					function = "gpio20_func";
				};

				conf {
					groups = "gpio20_group";
					input-enable = <0x01>;
					bias-pull-down = <0x01>;
				};
			};

			gpio21-default {

				mux {
					groups = "gpio21_group";
					function = "gpio21_func";
				};

				conf {
					groups = "gpio21_group";
					input-enable = <0x01>;
					bias-pull-down = <0x01>;
				};
			};

			gpio22-default {

				mux {
					groups = "gpio22_group";
					function = "gpio22_func";
				};
			};

			gpio23-default {

				mux {
					groups = "gpio23_group";
					function = "gpio23_func";
				};
			};

			gpio24-default {

				mux {
					groups = "gpio24_group";
					function = "gpio24_func";
				};
			};

			gpio25-default {

				mux {
					groups = "gpio25_group";
					function = "gpio25_func";
				};
			};

			gpio26-default {

				mux {
					groups = "gpio26_group";
					function = "gpio26_func";
				};
			};

			gpio27-default {

				mux {
					groups = "gpio27_group";
					function = "gpio27_func";
				};
			};

			gpio28-default {
				phandle = <0x22>;

				mux {
					groups = "gpio28_group";
					function = "gpio28_func";
				};

				conf {
					groups = "gpio28_group";
					input-enable = <0x01>;
					bias-pull-up = <0x01>;
				};
			};

			gpio29-default {

				mux {
					groups = "gpio29_group";
					function = "gpio29_func";
				};
			};

			gpio30-default {

				mux {
					groups = "gpio30_group";
					function = "gpio30_func";
				};
			};

			gpio31-default {

				mux {
					groups = "gpio31_group";
					function = "gpio31_func";
				};
			};

			gpio32-default {

				mux {
					groups = "gpio32_group";
					function = "gpio32_func";
				};
			};

			gpio33-default {

				mux {
					groups = "gpio33_group";
					function = "gpio33_func";
				};
			};

			gpio34-default {

				mux {
					groups = "gpio34_group";
					function = "gpio34_func";
				};
			};

			gpio35-default {
				phandle = <0x2c>;

				mux {
					groups = "gpio35_group";
					function = "gpio35_func";
				};

				conf {
					groups = "gpio35_group";
					input-enable = <0x01>;
					bias-pull-down = <0x01>;
				};
			};

			gpio36-default {
				phandle = <0x2d>;

				mux {
					groups = "gpio36_group";
					function = "gpio36_func";
				};

				conf {
					groups = "gpio36_group";
					input-enable = <0x01>;
					bias-pull-down = <0x01>;
				};
			};

			gpio37-default {
				phandle = <0x2e>;

				mux {
					groups = "gpio37_group";
					function = "gpio37_func";
				};

				conf {
					groups = "gpio37_group";
					input-enable = <0x01>;
					bias-pull-down = <0x01>;
				};
			};

			gpio38-default {
				phandle = <0x2f>;

				mux {
					groups = "gpio38_group";
					function = "gpio38_func";
				};

				conf {
					groups = "gpio38_group";
					input-enable = <0x01>;
					bias-pull-down = <0x01>;
				};
			};

			gpio39-default {
				phandle = <0x30>;

				mux {
					groups = "gpio39_group";
					function = "gpio39_func";
				};

				conf {
					groups = "gpio39_group";
					input-enable = <0x01>;
					bias-pull-down = <0x01>;
				};
			};

			gpio40-default {
				phandle = <0x31>;

				mux {
					groups = "gpio40_group";
					function = "gpio40_func";
				};

				conf {
					groups = "gpio40_group";
					input-enable = <0x01>;
					bias-pull-down = <0x01>;
				};
			};

			gpio41-default {
				phandle = <0x32>;

				mux {
					groups = "gpio41_group";
					function = "gpio41_func";
				};
			};

			gpio42-default {

				mux {
					groups = "gpio42_group";
					function = "gpio42_func";
				};

				conf {
					groups = "gpio42_group";
					input-enable = <0x01>;
					bias-pull-down = <0x01>;
				};
			};

			gpio43-default {
				phandle = <0x52>;

				mux {
					groups = "gpio43_group";
					function = "gpio43_func";
				};
			};

			gpio44-default {

				mux {
					groups = "gpio44_group";
					function = "gpio44_func";
				};
			};

			gpio45-default {

				mux {
					groups = "gpio45_group";
					function = "gpio45_func";
				};
			};

			gpio46-default {

				mux {
					groups = "gpio46_group";
					function = "gpio46_func";
				};

				conf {
					groups = "gpio46_group";
					input-enable = <0x01>;
					bias-pull-down = <0x01>;
				};
			};

			gpio47-default {

				mux {
					groups = "gpio47_group";
					function = "gpio47_func";
				};

				conf {
					groups = "gpio47_group";
					input-enable = <0x01>;
					bias-pull-down = <0x01>;
				};
			};

			gpio48-default {

				mux {
					groups = "gpio48_group";
					function = "gpio48_func";
				};
			};

			gpio49-default {

				mux {
					groups = "gpio49_group";
					function = "gpio49_func";
				};
			};

			gpio50-default {

				mux {
					groups = "gpio50_group";
					function = "gpio50_func";
				};
			};

			gpio51-default {

				mux {
					groups = "gpio51_group";
					function = "gpio51_func";
				};
			};

			gpio52-default {
				phandle = <0x33>;

				mux {
					groups = "gpio52_group";
					function = "gpio52_func";
				};

				conf {
					groups = "gpio52_group";
					input-enable = <0x01>;
					bias-pull-down = <0x01>;
				};
			};

			gpio53-default {
				phandle = <0x34>;

				mux {
					groups = "gpio53_group";
					function = "gpio53_func";
				};

				conf {
					groups = "gpio53_group";
					input-enable = <0x01>;
					bias-pull-down = <0x01>;
				};
			};

			gpio54-default {

				mux {
					groups = "gpio54_group";
					function = "gpio54_func";
				};
			};

			gpio55-default {

				mux {
					groups = "gpio55_group";
					function = "gpio55_func";
				};
			};

			gpio56-default {

				mux {
					groups = "gpio56_group";
					function = "gpio56_func";
				};
			};

			gpio57-default {

				mux {
					groups = "gpio57_group";
					function = "gpio57_func";
				};
			};

			gpio58-default {

				mux {
					groups = "gpio58_group";
					function = "gpio58_func";
				};
			};

			gpio59-default {

				mux {
					groups = "gpio59_group";
					function = "gpio59_func";
				};
			};

			gpio60-default {

				mux {
					groups = "gpio60_group";
					function = "gpio60_func";
				};
			};

			gpio61-default {

				mux {
					groups = "gpio61_group";
					function = "gpio61_func";
				};
			};

			gpio62-default {

				mux {
					groups = "gpio62_group";
					function = "gpio62_func";
				};
			};

			gpio63-default {

				mux {
					groups = "gpio63_group";
					function = "gpio63_func";
				};
			};

			gpio64-default {
				phandle = <0x35>;

				mux {
					groups = "gpio64_group";
					function = "gpio64_func";
				};

				conf {
					groups = "gpio64_group";
					input-enable = <0x01>;
					bias-pull-down = <0x01>;
				};
			};

			gpio65-default {
				phandle = <0x36>;

				mux {
					groups = "gpio65_group";
					function = "gpio65_func";
				};

				conf {
					groups = "gpio65_group";
					input-enable = <0x01>;
					bias-pull-down = <0x01>;
				};
			};

			gpio66-default {
				phandle = <0x37>;

				mux {
					groups = "gpio66_group";
					function = "gpio66_func";
				};

				conf {
					groups = "gpio66_group";
					input-enable = <0x01>;
					bias-pull-down = <0x01>;
				};
			};

			gpio67-default {
				phandle = <0x38>;

				mux {
					groups = "gpio67_group";
					function = "gpio67_func";
				};

				conf {
					groups = "gpio67_group";
					input-enable = <0x01>;
					bias-pull-down = <0x01>;
				};
			};

			gpio68-default {

				mux {
					groups = "gpio68_group";
					function = "gpio68_func";
				};
			};

			gpio69-default {

				mux {
					groups = "gpio69_group";
					function = "gpio69_func";
				};
			};

			gpio70-default {
				phandle = <0x39>;

				mux {
					groups = "gpio70_group";
					function = "gpio70_func";
				};
			};

			gpio71-default {

				mux {
					groups = "gpio71_group";
					function = "gpio71_func";
				};
			};

			gpio72-default {

				mux {
					groups = "gpio72_group";
					function = "gpio72_func";
				};
			};

			gpio73-default {
				phandle = <0x3a>;

				mux {
					groups = "gpio73_group";
					function = "gpio73_func";
				};
			};

			gpio74-default {

				mux {
					groups = "gpio74_group";
					function = "gpio74_func";
				};
			};

			gpio75-default {

				mux {
					groups = "gpio75_group";
					function = "gpio75_func";
				};
			};

			gpio76-default {

				mux {
					groups = "gpio76_group";
					function = "gpio76_func";
				};
			};

			gpio77-default {

				mux {
					groups = "gpio77_group";
					function = "gpio77_func";
				};
			};

			gpio78-default {

				mux {
					groups = "gpio78_group";
					function = "gpio78_func";
				};
			};

			gpio79-default {

				mux {
					groups = "gpio79_group";
					function = "gpio79_func";
				};
			};

			gpio80-default {

				mux {
					groups = "gpio80_group";
					function = "gpio80_func";
				};
			};

			gpio81-default {

				mux {
					groups = "gpio81_group";
					function = "gpio81_func";
				};
			};

			gpio82-default {
				phandle = <0x4c>;

				mux {
					groups = "gpio82_group";
					function = "gpio82_func";
				};
			};

			gpio83-default {
				phandle = <0x3b>;

				mux {
					groups = "gpio83_group";
					function = "gpio83_func";
				};
			};

			gpio84-default {

				mux {
					groups = "gpio84_group";
					function = "gpio84_func";
				};
			};

			gpio85-default {
				phandle = <0x4d>;

				mux {
					groups = "gpio85_group";
					function = "gpio85_func";
				};
			};

			gpio86-default {
				phandle = <0x3c>;

				mux {
					groups = "gpio86_group";
					function = "gpio86_func";
				};
			};

			gpio87-default {
				phandle = <0x3d>;

				mux {
					groups = "gpio87_group";
					function = "gpio87_func";
				};
			};

			gpio88-default {

				mux {
					groups = "gpio88_group";
					function = "gpio88_func";
				};
			};

			gpio89-default {

				mux {
					groups = "gpio89_group";
					function = "gpio89_func";
				};
			};

			gpio90-default {

				mux {
					groups = "gpio90_group";
					function = "gpio90_func";
				};
			};

			gpio91-default {

				mux {
					groups = "gpio91_group";
					function = "gpio91_func";
				};
			};

			gpio92-default {
				phandle = <0x3e>;

				mux {
					groups = "gpio92_group";
					function = "gpio92_func";
				};

				conf {
					groups = "gpio92_group";
					input-enable = <0x01>;
					bias-pull-down = <0x01>;
				};
			};

			gpio93-default {
				phandle = <0x3f>;

				mux {
					groups = "gpio93_group";
					function = "gpio93_func";
				};

				conf {
					groups = "gpio93_group";
					input-enable = <0x01>;
					bias-pull-down = <0x01>;
				};
			};

			gpio94-default {

				mux {
					groups = "gpio94_group";
					function = "gpio94_func";
				};

				conf {
					groups = "gpio94_group";
					input-enable = <0x00>;
					bias-pull-down = <0x01>;
				};
			};

			gpio95-default {

				mux {
					groups = "gpio95_group";
					function = "gpio95_func";
				};
			};

			gpio96-default {

				mux {
					groups = "gpio96_group";
					function = "gpio96_func";
				};
			};

			gpio97-default {

				mux {
					groups = "gpio97_group";
					function = "gpio97_func";
				};
			};

			gpio98-default {

				mux {
					groups = "gpio98_group";
					function = "gpio98_func";
				};
			};

			gpio99-default {

				mux {
					groups = "gpio99_group";
					function = "gpio99_func";
				};
			};

			gpio100-default {

				mux {
					groups = "gpio100_group";
					function = "gpio100_func";
				};
			};

			gpio101-default {

				mux {
					groups = "gpio101_group";
					function = "gpio101_func";
				};
			};

			gpio102-default {

				mux {
					groups = "gpio102_group";
					function = "gpio102_func";
				};
			};

			gpio103-default {

				mux {
					groups = "gpio103_group";
					function = "gpio103_func";
				};
			};

			gpio104-default {

				mux {
					groups = "gpio104_group";
					function = "gpio104_func";
				};
			};

			gpio105-default {

				mux {
					groups = "gpio105_group";
					function = "gpio105_func";
				};
			};

			gpio106-default {
				phandle = <0x17>;

				mux {
					groups = "gpio106_group";
					function = "gpio106_func";
				};

				conf {
					groups = "gpio106_group";
					input-enable = <0x00>;
					bias-pull-down = <0x01>;
				};
			};

			gpio107-default {

				mux {
					groups = "gpio107_group";
					function = "gpio107_func";
				};

				conf {
					groups = "gpio107_group";
					input-enable = <0x01>;
					bias-pull-down = <0x01>;
				};
			};

			gpio108-default {

				mux {
					groups = "gpio108_group";
					function = "gpio108_func";
				};

				conf {
					groups = "gpio108_group";
					input-enable = <0x01>;
					bias-pull-down = <0x01>;
				};
			};

			gpio109-default {

				mux {
					groups = "gpio109_group";
					function = "gpio109_func";
				};

				conf {
					groups = "gpio109_group";
					input-enable = <0x01>;
					bias-pull-down = <0x01>;
				};
			};

			gpio110-default {

				mux {
					groups = "gpio110_group";
					function = "gpio110_func";
				};

				conf {
					groups = "gpio110_group";
					input-enable = <0x01>;
					bias-pull-down = <0x01>;
				};
			};

			gpio111-default {
				phandle = <0x1b>;

				mux {
					groups = "gpio111_group";
					function = "gpio111_func";
				};

				conf {
					groups = "gpio111_group";
					input-enable = <0x00>;
					bias-pull-up = <0x01>;
				};
			};

			csi_mon_out-default {

				mux {
					groups = "csi_mon_out_group";
					function = "csi_mon_out_func";
				};
			};

			csi_ocla_clk-default {

				mux {
					groups = "csi_ocla_clk_group";
					function = "csi_ocla_clk_func";
				};
			};

			csi_mon_out_valid-default {

				mux {
					groups = "csi_mon_out_valid_group";
					function = "csi_mon_out_valid_func";
				};
			};

			csi_parity_error-default {

				mux {
					groups = "csi_parity_error_group";
					function = "csi_parity_error_func";
				};
			};

			csi_dtb_out-default {

				mux {
					groups = "csi_dtb_out_group";
					function = "csi_dtb_out_func";
				};
			};

			csi_phy_sel-default {

				mux {
					groups = "csi_phy_sel_group";
					function = "csi_phy_sel_func";
				};
			};

			vc_g2d0_debug_out-default {

				mux {
					groups = "vc_g2d0_debug_out_group";
					function = "vc_g2d0_debug_out_func";
				};
			};

			vc_g2d1_debug_out-default {

				mux {
					groups = "vc_g2d1_debug_out_group";
					function = "vc_g2d1_debug_out_func";
				};
			};

			sata_mpll_clk-default {

				mux {
					groups = "sata_mpll_clk_group";
					function = "sata_mpll_clk_func";
				};
			};

			sata_ref_repeat_clk_m-default {

				mux {
					groups = "sata_ref_repeat_clk_m_group";
					function = "sata_ref_repeat_clk_m_func";
				};
			};

			sata_ref_repeat_clk_p-default {

				mux {
					groups = "sata_ref_repeat_clk_p_group";
					function = "sata_ref_repeat_clk_p_func";
				};
			};
		};

		gpio@51600000 {
			#address-cells = <0x01>;
			#size-cells = <0x00>;
			compatible = "snps,dw-apb-gpio";
			reg = <0x00 0x51600000 0x00 0x80>;
			status = "okay";

			gpio-port@0 {
				compatible = "snps,dw-apb-gpio-port";
				gpio-controller;
				#gpio-cells = <0x02>;
				ngpios = <0x20>;
				reg = <0x00>;
				interrupt-parent = <0x10>;
				interrupts = <0x12f 0x130 0x131 0x132 0x133 0x134 0x135 0x136 0x137 0x138 0x139 0x13a 0x13b 0x13c 0x13d 0x13e 0x13f 0x140 0x141 0x142 0x143 0x144 0x145 0x146 0x147 0x148 0x149 0x14a 0x14b 0x14c 0x14d 0x14e>;
				phandle = <0x23>;
			};

			gpio-port@1 {
				compatible = "snps,dw-apb-gpio-port";
				gpio-controller;
				#gpio-cells = <0x02>;
				ngpios = <0x20>;
				reg = <0x01>;
				phandle = <0x53>;
			};

			gpio-port@2 {
				compatible = "snps,dw-apb-gpio-port";
				gpio-controller;
				#gpio-cells = <0x02>;
				ngpios = <0x20>;
				reg = <0x02>;
				phandle = <0x4e>;
			};

			gpio-port@3 {
				compatible = "snps,dw-apb-gpio-port";
				gpio-controller;
				#gpio-cells = <0x02>;
				ngpios = <0x10>;
				reg = <0x03>;
				phandle = <0x18>;
			};
		};

		pwm@0x50818000 {
			compatible = "eswin,pwm-eswin";
			#pwm-cells = <0x02>;
			clock-names = "pwm", "pclk";
			clocks = <0x01 0x2a6>;
			clock-frequency = <0xbebc200>;
			pinctrl-names = "default";
			pinctrl-0 = <0x40>;
			reg = <0x00 0x50818000 0x00 0x4000>;
			resets = <0x12 0x0f 0x01>;
			reset-names = "pwmrst";
			status = "okay";
			phandle = <0x1f>;
		};

		watchdog@0x50800000 {
			compatible = "snps,dw-wdt";
			reg = <0x00 0x50800000 0x00 0x4000>;
			clocks = <0x01 0x298>;
			clock-names = "pclk";
			resets = <0x12 0x11 0x01>;
			reset-names = "rst";
			interrupts = <0x57>;
			interrupt-parent = <0x10>;
			status = "okay";
		};

		watchdog@0x50804000 {
			compatible = "snps,dw-wdt";
			reg = <0x00 0x50804000 0x00 0x4000>;
			clocks = <0x01 0x299>;
			clock-names = "pclk";
			resets = <0x12 0x11 0x02>;
			reset-names = "rst";
			interrupts = <0x58>;
			interrupt-parent = <0x10>;
			status = "okay";
		};

		watchdog@0x50808000 {
			compatible = "snps,dw-wdt";
			reg = <0x00 0x50808000 0x00 0x4000>;
			clocks = <0x01 0x29a>;
			clock-names = "pclk";
			resets = <0x12 0x11 0x04>;
			reset-names = "rst";
			interrupts = <0x59>;
			interrupt-parent = <0x10>;
			status = "okay";
		};

		watchdog@0x5080c000 {
			compatible = "snps,dw-wdt";
			reg = <0x00 0x5080c000 0x00 0x4000>;
			clocks = <0x01 0x29b>;
			clock-names = "pclk";
			resets = <0x12 0x11 0x08>;
			reset-names = "rst";
			interrupts = <0x5a>;
			interrupt-parent = <0x10>;
			status = "okay";
		};

		rtc@51818000 {
			compatible = "eswin,eic7700-rtc";
			reg = <0x00 0x51818000 0x00 0x400>;
			eswin,syscfg = <0x11 0x3c0>;
			interrupt-parent = <0x10>;
			interrupts = <0x124>;
			clocks = <0x01 0x272>;
			clock-names = "rtcclk";
			clock-frequency = <0x3d09>;
			resets = <0x12 0x34 0x01>;
			reset-names = "rtcrst";
			status = "okay";
		};

		i2s0@50200000 {
			compatible = "snps,i2s";
			clocks = <0x01 0x250>;
			clock-names = "mclk";
			#address-cells = <0x01>;
			#size-cells = <0x00>;
			#sound-dai-cells = <0x00>;
			reg = <0x00 0x50200000 0x00 0x10000>;
			dma-names = "rx", "tx";
			dmas = <0x1d 0x04 0x00 0x1d 0x05 0x00>;
			vo_mclk_sel,syscrg = <0x15 0x1bc>;
			resets = <0x12 0x22 0x01 0x12 0x22 0x02 0x12 0x21 0x02>;
			reset-names = "i2srst", "i2sprst", "voprst";
			status = "okay";

			port {
				phandle = <0x44>;

				endpoint {
					remote-endpoint = <0x41>;
					dai-format = "i2s";
					phandle = <0x51>;
				};
			};
		};

		i2s1@50210000 {
			compatible = "snps,i2s";
			clocks = <0x01 0x250>;
			clock-names = "mclk";
			#address-cells = <0x01>;
			#size-cells = <0x00>;
			#sound-dai-cells = <0x00>;
			reg = <0x00 0x50210000 0x00 0x10000>;
			dma-names = "rx", "tx";
			dmas = <0x1d 0x02 0x01 0x1d 0x03 0x01>;
			vo_mclk_sel,syscrg = <0x15 0x1bc>;
			resets = <0x12 0x22 0x01 0x12 0x22 0x02 0x12 0x21 0x02>;
			reset-names = "i2srst", "i2sprst", "voprst";
			status = "okay";

			port {
				phandle = <0x43>;

				endpoint {
					remote-endpoint = <0x42>;
					dai-format = "i2s";
					phandle = <0x24>;
				};
			};
		};

		i2s2@50220000 {
			compatible = "snps,i2s";
			clocks = <0x01 0x250>;
			clock-names = "mclk";
			#address-cells = <0x01>;
			#size-cells = <0x00>;
			#sound-dai-cells = <0x00>;
			reg = <0x00 0x50220000 0x00 0x10000>;
			dma-names = "rx", "tx";
			dmas = <0x1d 0x00 0x02 0x1d 0x01 0x02>;
			vo_mclk_sel,syscrg = <0x15 0x1bc>;
			resets = <0x12 0x22 0x01 0x12 0x22 0x02 0x12 0x21 0x02>;
			reset-names = "i2srst", "i2sprst", "voprst";
			status = "disabled";
		};

		graphcard0 {
			compatible = "audio-graph-card";
			status = "okay";
			dais = <0x43>;
		};

		graphcard1 {
			compatible = "audio-graph-card";
			status = "okay";
			dais = <0x44>;
		};

		graphcard2 {
			compatible = "audio-graph-card";
			status = "disabled";
		};

		display-subsystem {
			compatible = "eswin,display-subsystem";
			ports = <0x45>;
			status = "okay";
		};

		display_control@502c0000 {
			compatible = "eswin,dc";
			reg = <0x00 0x502c0000 0x00 0x100 0x00 0x502c0180 0x00 0x700 0x00 0x502c1400 0x00 0x1400>;
			interrupt-parent = <0x10>;
			interrupts = <0xee>;
			clocks = <0x01 0x24d 0x01 0x24f 0x01 0x24c 0x01 0x04 0x01 0x2a>;
			clock-names = "cfg_clk", "pix_clk", "axi_clk", "spll0_fout1", "vo_mux";
			resets = <0x12 0x23 0x01 0x12 0x23 0x02 0x12 0x23 0x04 0x12 0x23 0x08>;
			reset-names = "vo_arst", "vo_prst", "dc_arst", "dc_prst";
			status = "okay";

			port {
				#address-cells = <0x01>;
				#size-cells = <0x00>;
				phandle = <0x45>;

				endpoint@0 {
					reg = <0x00>;
					remote-endpoint = <0x46>;
					phandle = <0x4a>;
				};

				endpoint@1 {
					reg = <0x01>;
					remote-endpoint = <0x47>;
					phandle = <0x49>;
				};

				endpoint@2 {
					reg = <0x02>;
					remote-endpoint = <0x48>;
					phandle = <0x50>;
				};
			};
		};

		es_wb {
			compatible = "eswin,virtual_display";
			bpp = [08];
			status = "disabled";

			port {

				endpoint {
					remote-endpoint = <0x49>;
					phandle = <0x47>;
				};
			};
		};

		dsi-output {
			compatible = "eswin,dsi-encoder";
			status = "okay";
		};

		mipi_dsi@50270000 {
			#address-cells = <0x01>;
			#size-cells = <0x00>;
			compatible = "eswin,dsi";
			reg = <0x00 0x50270000 0x00 0x10000>;
			clocks = <0x01 0x201>;
			clock-names = "pclk";
			resets = <0x12 0x21 0x01>;
			reset-names = "phyrstn";
			status = "okay";

			ports {
				#address-cells = <0x01>;
				#size-cells = <0x00>;

				port@0 {
					#address-cells = <0x01>;
					#size-cells = <0x00>;
					reg = <0x00>;

					endpoint {
						remote-endpoint = <0x4a>;
						phandle = <0x46>;
					};
				};

				port@1 {
					#address-cells = <0x01>;
					#size-cells = <0x00>;
					reg = <0x01>;

					endpoint {
						remote-endpoint = <0x4b>;
						phandle = <0x4f>;
					};
				};
			};

			dsi_panel@0 {
				compatible = "eswin,generic-panel";
				reg = <0x00>;
				status = "okay";
				pinctrl-names = "default";
				pinctrl-0 = <0x4c 0x4d>;
				backlight0-gpios = <0x4e 0x12 0x00>;
				rst-gpios = <0x4e 0x15 0x00>;

				port {

					endpoint {
						remote-endpoint = <0x4f>;
						phandle = <0x4b>;
					};
				};
			};
		};

		hdmi@502a0000 {
			compatible = "eswin,eswin-dw-hdmi";
			reg = <0x00 0x502a0000 0x00 0x20000>;
			pinctrl-names = "default";
			interrupt-parent = <0x10>;
			interrupts = <0x112>;
			clocks = <0x01 0x24d 0x01 0x252 0x01 0x251>;
			clock-names = "iahb", "cec", "isfr";
			reg-io-width = <0x04>;
			ddc-i2c-scl-high-time-ns = <0x1264>;
			ddc-i2c-scl-low-time-ns = <0x1334>;
			#sound-dai-cells = <0x00>;
			resets = <0x12 0x21 0x08 0x12 0x21 0x10 0x12 0x21 0x20>;
			reset-names = "prstn", "phyrstn", "rstn";
			status = "okay";

			ports {
				#address-cells = <0x01>;
				#size-cells = <0x00>;

				port@0 {
					reg = <0x00>;

					endpoint@0 {
						remote-endpoint = <0x50>;
						phandle = <0x48>;
					};
				};

				port@2 {
					reg = <0x02>;

					endpoint@1 {
						system-clock-frequency = <0xbb8000>;
						remote-endpoint = <0x51>;
						phandle = <0x41>;
					};
				};
			};
		};

		hdmi-hdcp2@50290000 {
			compatible = "eswin,dw-hdmi-hdcp2";
			reg = <0x00 0x50290000 0x00 0x10000>;
			interrupt-parent = <0x10>;
			interrupts = <0x113>;
			clocks = <0x01 0x24d 0x01 0x24e>;
			clock-names = "pclk_hdcp2", "hdcp2_clk_hdmi";
			status = "disabled";
		};

		usb0@50480000 {
			compatible = "eswin,eic7700-dwc3";
			#address-cells = <0x02>;
			#size-cells = <0x02>;
			clocks = <0x01 0x10e>;
			clock-names = "suspend";
			eswin,hsp_sp_csr = <0x14 0x800 0x808 0x83c 0x840>;
			resets = <0x12 0x07 0x8000>;
			reset-names = "vaux";
			ranges;
			status = "okay";

			dwc3@50480000 {
				compatible = "snps,dwc3";
				reg = <0x00 0x50480000 0x00 0x10000>;
				#address-cells = <0x02>;
				#size-cells = <0x02>;
				interrupt-parent = <0x10>;
				interrupts = <0x55>;
				interrupt-names = "peripheral";
				dr_mode = "host";
				phy_type = "utmi";
				maximum-speed = "super-speed";
				iommus = <0x13 0x0a>;
				eswin,hsp_sp_csr = <0x14 0x1044>;
				dma-ranges = <0x00 0x00 0x00 0xc0000000 0x200 0x00>;
				snps,dis_enblslpm_quirk;
				snps,dis-u2-freeclk-exists-quirk;
				snps,dis_u2_susphy_quirk;
				snps,dis-del-phy-power-chg-quirk;
				snps,parkmode-disable-ss-quirk;
				status = "okay";
				numa-node-id = <0x00>;
				tbus = <0x02>;
			};
		};

		usb1@50490000 {
			compatible = "eswin,eic7700-dwc3";
			#address-cells = <0x02>;
			#size-cells = <0x02>;
			clocks = <0x01 0x10f>;
			clock-names = "suspend";
			eswin,hsp_sp_csr = <0x14 0x900 0x908 0x93c 0x940>;
			resets = <0x12 0x07 0x10000>;
			reset-names = "vaux";
			ranges;
			status = "okay";

			dwc3@50490000 {
				compatible = "snps,dwc3";
				reg = <0x00 0x50490000 0x00 0x10000>;
				#address-cells = <0x02>;
				#size-cells = <0x02>;
				interrupt-parent = <0x10>;
				interrupts = <0x56>;
				interrupt-names = "host";
				dr_mode = "host";
				phy_type = "utmi";
				maximum-speed = "super-speed";
				iommus = <0x13 0x0b>;
				eswin,hsp_sp_csr = <0x14 0x1048>;
				dma-ranges = <0x00 0x00 0x00 0xc0000000 0x200 0x00>;
				snps,dis_enblslpm_quirk;
				snps,dis-u2-freeclk-exists-quirk;
				snps,dis_u2_susphy_quirk;
				snps,dis-del-phy-power-chg-quirk;
				snps,parkmode-disable-ss-quirk;
				status = "okay";
				numa-node-id = <0x00>;
				tbus = <0x02>;

				usb-hub {
					gpio-hog;
					pinctrl-names = "default";
					pinctrl-0 = <0x52>;
					gpios = <0x53 0x0b 0x00>;
					output-low;
					line-name = "usb-hub-reset";
				};
			};
		};
	};

	opp-table0 {
		compatible = "operating-points-v2";
		opp-shared;
		phandle = <0x03>;

		opp-24000000 {
			opp-hz = <0x00 0x16e3600>;
			opp-microvolt = "", "\f5";
			clock-latency-ns = <0x11170>;
		};

		opp-100000000 {
			opp-hz = <0x00 0x5f5e100>;
			opp-microvolt = "", "\f5";
			clock-latency-ns = <0x11170>;
		};

		opp-200000000 {
			opp-hz = <0x00 0xbebc200>;
			opp-microvolt = "", "\f5";
			clock-latency-ns = <0x11170>;
		};

		opp-400000000 {
			opp-hz = <0x00 0x17d78400>;
			opp-microvolt = "", "\f5";
			clock-latency-ns = <0x11170>;
		};

		opp-500000000 {
			opp-hz = <0x00 0x1dcd6500>;
			opp-microvolt = "", "\f5";
			clock-latency-ns = <0x11170>;
		};

		opp-600000000 {
			opp-hz = <0x00 0x23c34600>;
			opp-microvolt = "", "\f5";
			clock-latency-ns = <0x11170>;
		};

		opp-700000000 {
			opp-hz = <0x00 0x29b92700>;
			opp-microvolt = "", "\f5";
			clock-latency-ns = <0x11170>;
		};

		opp-800000000 {
			opp-hz = <0x00 0x2faf0800>;
			opp-microvolt = "", "\f5";
			clock-latency-ns = <0x11170>;
		};

		opp-900000000 {
			opp-hz = <0x00 0x35a4e900>;
			opp-microvolt = "", "\f5";
			clock-latency-ns = <0x11170>;
		};

		opp-1000000000 {
			opp-hz = <0x00 0x3b9aca00>;
			opp-microvolt = "", "\f5";
			clock-latency-ns = <0x11170>;
		};

		opp-1200000000 {
			opp-hz = <0x00 0x47868c00>;
			opp-microvolt = "", "\f5";
			clock-latency-ns = <0x11170>;
		};

		opp-1300000000 {
			opp-hz = <0x00 0x4d7c6d00>;
			opp-microvolt = "", "\f5";
			clock-latency-ns = <0x11170>;
		};

		opp-1400000000 {
			opp-hz = <0x00 0x53724e00>;
			opp-microvolt = "", "\f5";
			clock-latency-ns = <0x11170>;
		};
	};

	aliases {
		serial0 = "/soc/serial@0x50900000";
		ethernet0 = "/soc/ethernet@50400000";
		ethernet1 = "/soc/ethernet@50410000";
	};

	chosen {
		stdout-path = "serial0:115200n8";
		xen,xen-bootargs = "com1=poll sched=null";
		
		DOMU1 {
			#address-cells = <0x01>;
			#size-cells = <0x01>;
			compatible = "xen,domain";
			memory = <0x00 0x40000>;
			cpus = <0x01>;
			vsbi_uart; /* remove this line if not needed */
			
			module@0x90400000 {
				compatible = "multiboot,module", "multiboot,ramdisk";
				reg = <0x90400000 0x659000>;
			};
			
			module@0x808ef000 {
				bootargs = "rw root=/dev/ram console=hvc0 earlycon=sbi earlyprintk keep_bootcon bootmem_debug debug";
				compatible = "multiboot,module", "multiboot,kernel";
				reg = <0x808ef000 0x68ff6d>;
			};
		};
	};

	memory@80000000 {
		device_type = "memory";
		reg = <0x00 0x80000000 0x7f 0x80000000>;
	};

	reserved-memory {
		#address-cells = <0x02>;
		#size-cells = <0x02>;
		ranges;

		linux,cma {
			compatible = "shared-dma-pool";
			reusable;
			size = <0x00 0x20000000>;
			alignment = <0x00 0x1000>;
			linux,cma-default;
		};

		sprammemory@59000000 {
			no-map;
			reg = <0x00 0x59000000 0x00 0x400000>;
		};

		lpcpu@a0000000 {
			no-map;
			reg = <0x00 0xa0000000 0x00 0x100000>;
		};

		g2d_4GB_boundary_reserved_4k {
			no-map;
			reg = <0x00 0xfffff000 0x00 0x1000>;
		};
	};
};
